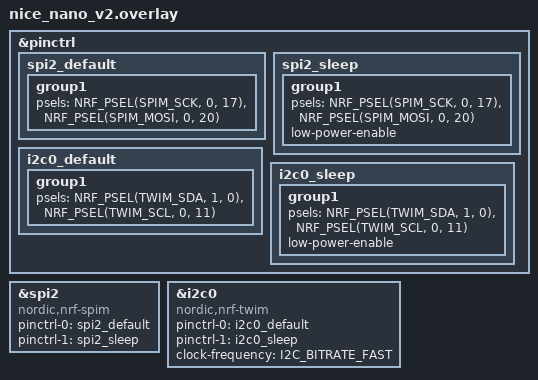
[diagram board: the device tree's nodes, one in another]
&pinctrl {
    spi2_default: spi2_default {
        group1 {
            psels = <NRF_PSEL(SPIM_SCK, 0, 17)>,
                    <NRF_PSEL(SPIM_MOSI, 0, 20)>;
        };
    };

    spi2_sleep: spi2_sleep {
        group1 {
            psels = <NRF_PSEL(SPIM_SCK, 0, 17)>,
                    <NRF_PSEL(SPIM_MOSI, 0, 20)>;
            low-power-enable;
        };
    };

    i2c0_default: i2c0_default {
        group1 {
            psels = <NRF_PSEL(TWIM_SDA, 1, 0)>,
                <NRF_PSEL(TWIM_SCL, 0, 11)>;
        };
    };

    i2c0_sleep: i2c0_sleep {
        group1 {
            psels = <NRF_PSEL(TWIM_SDA, 1, 0)>,
                <NRF_PSEL(TWIM_SCL, 0, 11)>;
            low-power-enable;
        };
    };
};

&spi2 {
    compatible = "nordic,nrf-spim";
    pinctrl-0 = <&spi2_default>;
    pinctrl-1 = <&spi2_sleep>;
    pinctrl-names = "default", "sleep";
};

&i2c0 {
    compatible = "nordic,nrf-twim";
    pinctrl-0 = <&i2c0_default>;
    pinctrl-1 = <&i2c0_sleep>;
    pinctrl-names = "default", "sleep";
    clock-frequency = <I2C_BITRATE_FAST>;
};
